# NUC029AN_v1 register map
File version: 1.0
Registers are 32-bit, read-write, reset 0x0 unless marked. A register's access mark holds for its fields unless they carry their own. Offsets are from the block's base; [hi:lo] are bit positions; 'fields as' and 'values as' point back to an identical list.

## UART0 — UART Register Map
Base 0x40050000
0x00 UA_RBR ro reset not defined — UART Receive Buffer Register
  [7:0] RBR — Receive Buffer Register (Read Only). By reading this register, the UART will return an 8-bit data received from RX pin (LSB first).
0x00 UA_THR wo reset not defined (alternate view of UA_RBR) — UART Transmit Holding Register
  [7:0] THR — Transmit Holding Register. By writing to this register, the UART will send out an 8-bit data through the TX pin (LSB first).
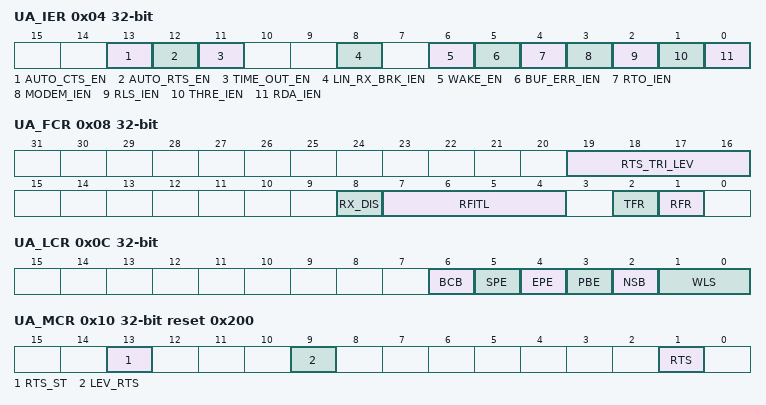
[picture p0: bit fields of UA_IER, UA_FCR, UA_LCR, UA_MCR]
0x04 UA_IER — UART Interrupt Enable Register
  [13] AUTO_CTS_EN — CTS Auto Flow Control Enable. When CTS auto-flow is enabled, the UART will send data to external device when CTS input assert (UART will not send data to device until CTS is asserted).
    0=Disable CTS auto flow control; 1=Enable CTS auto flow control
  [12] AUTO_RTS_EN — RTS Auto Flow Control Enable. When RTS auto-flow is enabled, if the number of bytes in the RX FIFO equals the UA_FCR [RTS_TRI_LEV], the UART will de-assert RTS signal.
    0=Disable RTS auto flow control; 1=Enable RTS auto flow control
  [11] TIME_OUT_EN — Time Out Counter Enable
    0=Disable Time-out counter; 1=Enable Time-out counter
  [8] LIN_RX_BRK_IEN — LIN RX Break Field Detected Interrupt Enable. Note: This field is used for LIN function mode.
    0=Mask off Lin bus RX break filed interrupt; 1=Enable Lin bus RX break filed interrupt
  [6] WAKE_EN — Wake Up CPU Function Enable
    0=Disable UART wake up CPU function; 1=Enable wake up function, when the system is in deep sleep mode, an external CTS change will wake up CPU from deep sleep mode
  [5] BUF_ERR_IEN — Buffer Error Interrupt Enable
    0=Mask off INT_BUF_ERR; 1=Enable INT_BUF_ERR
  [4] RTO_IEN — RX Time Out Interrupt Enable
    0=Mask off INT_TOUT; 1=Enable INT_TOUT
  [3] MODEM_IEN — Modem Status Interrupt Enable
    0=Mask off INT_MODEM; 1=Enable INT_MODEM
  [2] RLS_IEN — Receive Line Status Interrupt Enable
    0=Mask off INT_RLS; 1=Enable INT_RLS
  [1] THRE_IEN — Transmit Holding Register Empty Interrupt Enable
    0=Mask off INT_THRE; 1=Enable INT_THRE
  [0] RDA_IEN — Receive Data Available Interrupt Enable.
    0=Mask off INT_RDA; 1=Enable INT_RDA
0x08 UA_FCR — UART FIFO Control Register
  [19:16] RTS_TRI_LEV — RTS Trigger Level for Auto-flow Control Use
  [8] RX_DIS — Receiver Disable register. The receiver is disabled or not (set 1 is disable receiver). Note: This field is used for RS-485 Normal Multi-drop mode. It should be programmed before UA_ALT_CSR [RS-485_NMM] is programmed.
    0=Enable Receiver; 1=Disable Receiver
  [7:4] RFITL — RX FIFO Interrupt (INT_RDA) Trigger Level
  [2] TFR — TX Field Software Reset. When TX_RST is set, all the byte in the transmit FIFO and TX internal state machine are cleared. Note: This bit will auto clear needs at least 3 UART engine clock cycles.
    0=Writing 0 to this bit has no effect; 1=Writing 1 to this bit will reset the TX internal state machine and pointers
  [1] RFR — RX Field Software Reset. When RX_RST is set, all the byte in the receiver FIFO and RX internal state machine are cleared. Note: This bit will auto clear needs at least 3 UART engine clock cycles.
    0=Writing 0 to this bit has no effect; 1=Writing 1 to this bit will reset the RX internal state machine and pointers
0x0C UA_LCR — UART Line Control Register
  [6] BCB — Break Control Bit. When this bit is set to logic 1, the serial data output (TX) is forced to the Spacing State (logic 0). This bit acts only on TX and has no effect on the transmitter logic.
  [5] SPE — Stick Parity Enable
    0=Disable stick parity; 1=When bits PBE , EPE and SPE are set, the parity bit is transmitted and checked as cleared. When PBE and SPE are set and EPE is cleared, the parity bit is transmitted and checked as set
  [4] EPE — Even Parity Enable. This bit has effect only when bit 3 (parity bit enable) is set.
    0=Odd number of logic 1's are transmitted or checked in the data word and parity bits; 1=Even number of logic 1's are transmitted or checked in the data word and parity bits
  [3] PBE — Parity Bit Enable
    0=Parity bit is not generated (transmit data) or checked (receive data) during transfer; 1=Parity bit is generated or checked between the last data word bit and stop bit of the serial data
  [2] NSB — Number of "STOP bit"
    0=1 STOP bit; 1=2 STOP bits (1.5 STOP bits if WLS[1:0]=00)
  [1:0] WLS — Word Length Select
0x10 UA_MCR reset 0x200 — UART Modem Control Register
  [13] RTS_ST ro — RTS Pin State (Read Only). This bit is the output pin status of RTS.
  [9] LEV_RTS — RTS Trigger Level. This bit can change the RTS trigger level.
    0=low level triggered; 1=high level triggered
  [1] RTS — RTS (Request-To-Send) Signal
    0=Drive RTS pin to logic 1 (If the LEV_RTS set to low level triggered). Drive RTS pin to logic 0 (If the LEV_RTS set to high level triggered); 1=Drive RTS pin to logic 0 (If the LEV_RTS set to low level triggered). Drive RTS pin to logic 1 (If the LEV_RTS set to high level triggered)
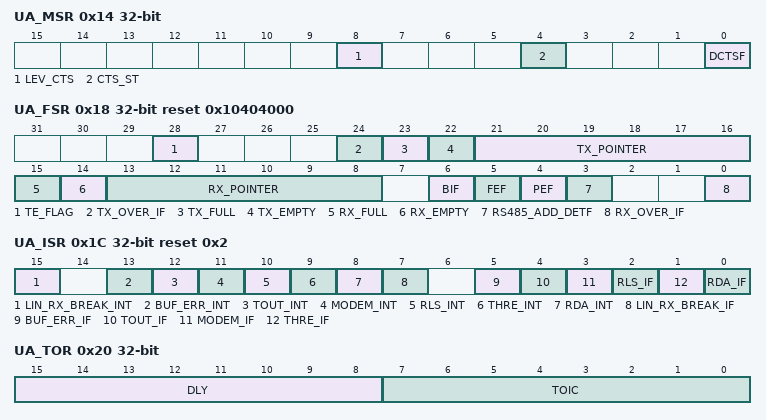
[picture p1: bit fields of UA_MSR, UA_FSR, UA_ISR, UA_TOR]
0x14 UA_MSR — UART Modem Status Register
  [8] LEV_CTS — CTS Trigger Level. This bit can change the CTS trigger level.
    0=low level triggered; 1=high level triggered
  [4] CTS_ST ro — CTS Pin Status (Read Only). This bit is the pin status of CTS when UART clock is enabled, and CTS multi-function port is selected.
  [0] DCTSF ro — Detect CTS State Change Flag (Read Only). This bit is set whenever CTS input has change state, and it will generate Modem interrupt to CPU when UA_IER [MODEM_IEN] is set to 1. Software can write 1 to clear this bit to zero
0x18 UA_FSR reset 0x10404000 — UART FIFO Status Register
  [28] TE_FLAG ro — Transmitter Empty Flag (Read Only). Bit is set by hardware when TX FIFO (UA_THR) is empty and the STOP bit of the last byte has been transmitted. Bit is cleared automatically when TX FIFO is not empty or the last byte transmission has not completed.
  [24] TX_OVER_IF ro — TX Overflow Error Interrupt Flag (Read Only). If TX FIFO (UA_THR) is full, an additional write to UA_THR will cause this bit to logic 1. Note: This bit is read only, but can be cleared by writing '1' to it.
  [23] TX_FULL ro — Transmitter FIFO Full (Read Only). This bit indicates TX FIFO full or not. This bit is set when TX_POINTER is equal to 16, otherwise is cleared by hardware.
  [22] TX_EMPTY ro — Transmitter FIFO Empty (Read Only). This bit indicates TX FIFO empty or not. When the last byte of TX FIFO has been transferred to Transmitter Shift Register, hardware sets this bit high. It will be cleared when writing data into THR (TX FIFO not empty).
  [21:16] TX_POINTER ro — TX FIFO Pointer (Read Only). This field indicates the TX FIFO Buffer Pointer. When CPU writes one byte into UA_THR, TX_POINTER increases one. When one byte of TX FIFO is transferred to Transmitter Shift Register, TX_POINTER decreases one. When TX_POINTER is equal to 16, TX_FULL is set. At this moment, TX_POINTER is cleared immediately by hardware.
  [15] RX_FULL ro — Receiver FIFO Full (Read Only). This bit initiates RX FIFO full or not. This bit is set when RX_POINTER is equal to 16, otherwise is cleared by hardware.
  [14] RX_EMPTY ro — Receiver FIFO Empty (Read Only). This bit initiate RX FIFO empty or not. When the last byte of RX FIFO has been read by CPU, hardware sets this bit high. It will be cleared when UART receives any new data.
  [13:8] RX_POINTER ro — RX FIFO Pointer (Read Only). This field indicates the RX FIFO Buffer Pointer. When UART receives one byte from external device, RX_POINTER increases one. When one byte of RX FIFO is read by CPU, RX_POINTER decreases one. When RX_POINTER is equal to 16, RX_FULL is set. At this moment, RX_POINTER is cleared immediately by hardware.
  [6] BIF ro — Break Interrupt Flag (Read Only). This bit is set to a logic 1 whenever the received data input(RX) is held in the "spacing state" (logic 0) for longer than a full word transmission time (that is, the total time of "start bit" + data bits + parity + stop bits) and is reset whenever the CPU writes 1 to this bit. Note: This bit is read only, but can be cleared by writing '1' to UA_FCR [RFR]
  [5] FEF ro — Framing Error Flag (Read Only). This bit is set to logic 1 whenever the received character does not have a valid "stop bit" (that is, the stop bit following the last data bit or parity bit is detected as a logic 0), and is reset whenever the CPU writes 1 to this bit. Note: This bit is read only, but can be cleared by writing '1' to UA_FCR [RFR]
  [4] PEF ro — Parity Error Flag (Read Only). This bit is set to logic 1 whenever the received character does not have a valid "parity bit", and is reset whenever the CPU writes 1 to this bit. Note: This bit is read only, but can be cleared by writing '1' to UA_FCR[RFR]
  [3] RS485_ADD_DETF ro — RS-485 Address Byte Detection Flag (Read Only). Note: This field is used for RS-485 function mode. Note: This bit is read only, but can be cleared by writing '1' to it.
  [0] RX_OVER_IF ro — RX Overflow Error IF (Read Only). This bit is set when RX FIFO overflow. If the number of bytes of received data is greater than RX_FIFO (UA_RBR) size, 64/16 bytes of UART0/UART1, this bit will be set. Note: This bit is read only, but can be cleared by writing '1' to it.
0x1C UA_ISR reset 0x2 — UART Interrupt Status Register
  [15] LIN_RX_BREAK_INT ro — LIN Bus RX Break Field Detected Interrupt Indicator (Read Only). This bit is set if LIN_RX_BRK_IEN and LIN_RX_BREAK_IF are both set to 1.
    0=No LIN RX Break interrupt is generated; 1=The LIN RX Break interrupt is generated
  [13] BUF_ERR_INT ro — Buffer Error Interrupt Indicator (Read Only). This bit is set if BUF_ERR_IEN and BUF_ERR_IF are both set to 1.
    0=No buffer error interrupt is generated; 1=The buffer error interrupt is generated
  [12] TOUT_INT ro — Time Out Interrupt Indicator (Read Only). This bit is set if TOUT_IEN and TOUT_IF are both set to 1.
    0=No Tout interrupt is generated; 1=The Tout interrupt is generated
  [11] MODEM_INT ro — MODEM Status Interrupt Indicator (Read Only). This bit is set if MODEM_IEN and MODEM_IF are both set to 1.
    0=No Modem interrupt is generated; 1=The Modem interrupt is generated
  [10] RLS_INT ro — Receive Line Status Interrupt Indicator (Read Only). This bit is set if RLS_IEN and RLS_IF are both set to 1.
    0=No RLS interrupt is generated; 1=The RLS interrupt is generated
  [9] THRE_INT ro — Transmit Holding Register Empty Interrupt Indicator (Read Only). This bit is set if THRE_IEN and THRE_IF are both set to 1.
    0=No THRE interrupt is generated; 1=The THRE interrupt is generated
  [8] RDA_INT ro — Receive Data Available Interrupt Indicator (Read Only). This bit is set if RDA_IEN and RDA_IF are both set to 1.
    0=No RDA interrupt is generated; 1=The RDA interrupt is generated
  [7] LIN_RX_BREAK_IF ro — LIN Bus RX Break Field Detected Flag (Read Only). This bit is set when RX received LIN Break Field. If UA_IER [LIN_RX_BRK_IEN] is enabled the LIN RX Break interrupt will be generated. Note: This bit is read only, but can be cleared by writing '1' to it.
  [5] BUF_ERR_IF ro — Buffer Error Interrupt Flag (Read Only). This bit is set when the TX or RX FIFO overflows or Break Interrupt Flag or Parity Error Flag or Frame Error Flag (TX_OVER_IF or RX_OVER_IF ) is set. When BUF_ERR_IF is set, the transfer is not correct. If UA_IER [BUF_ERR_IEN] is enabled, the buffer error interrupt will be generated.
  [4] TOUT_IF ro — Time Out Interrupt Flag (Read Only). This bit is set when the RX FIFO is not empty and no activities occurred in the RX FIFO and the time out counter equal to TOIC. If UA_IER [TOUT_IEN] is enabled, the Tout interrupt will be generated. Note: This bit is read only and user can read UA_RBR (RX is in active) to clear it.
  [3] MODEM_IF ro — MODEM Interrupt Flag (Read Only). Note: This bit is read only and reset to 0 when bit DCTSF is cleared by a write 1 on DCTSF.
  [2] RLS_IF ro — Receive Line Interrupt Flag (Read Only). This bit is set when the RX receive data have parity error, framing error or break error (at least one of 3 bits, BIF, FEF and PEF, is set). If UA_IER [RLS_IEN] is enabled, the RLS interrupt will be generated. Note: This bit is read only and reset to 0 when all bits of BIF, FEF and PEF are cleared.
  [1] THRE_IF ro — Transmit Holding Register Empty Interrupt Flag (Read Only). This bit is set when the last data of TX FIFO is transferred to Transmitter Shift Register. If UA_IER [THRE_IEN] is enabled, the THRE interrupt will be generated. Note: This bit is read only and it will be cleared when writing data into THR (TX FIFO not empty).
  [0] RDA_IF ro — Receive Data Available Interrupt Flag (Read Only). When the number of bytes in the RX FIFO equals the RFITL then the RDA_IF will be set. If UA_IER [RDA_IEN] is enabled, the RDA interrupt will be generated. Note: This bit is read only and it will be cleared when the number of unread bytes of RX FIFO drops below the threshold level (RFITL).
0x20 UA_TOR — UART Time Out Register
  [15:8] DLY — TX Delay time value. This field is use to programming the transfer delay time between the last stop bit and next start bit.
  [7:0] TOIC — Time Out Interrupt Comparator
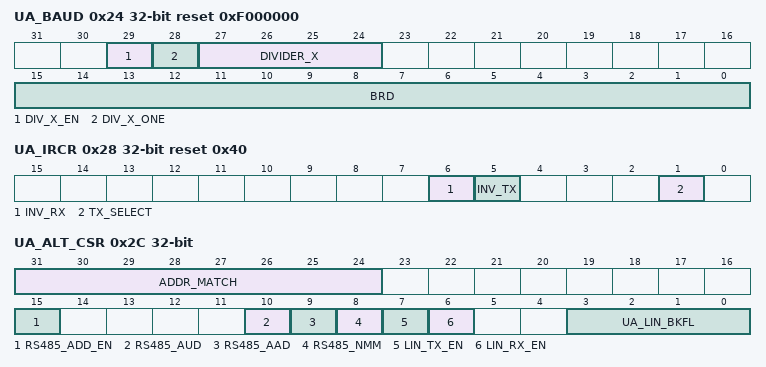
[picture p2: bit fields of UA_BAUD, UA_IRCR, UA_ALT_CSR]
0x24 UA_BAUD reset 0xF000000 — UART Baud Rate Divisor Register
  [29] DIV_X_EN — Divider X Enable. Refer to the table below for more information. Note: When in IrDA mode, this bit must disable.
    0=Disable divider X (the equation of M = 16); 1=Enable divider X (the equation of M = X+1, but DIVIDER_X [27:24] must = 8)
  [28] DIV_X_ONE — Divider X equal 1. Refer to the Table 6.114 below for more information.
    0=Divider M = X (the equation of M = X+1, but DIVIDER_X[27:24] must = 8); 1=Divider M = 1 (the equation of M = 1, but BRD [15:0] must = 3)
  [27:24] DIVIDER_X
  [15:0] BRD — Baud Rate Divider. The field indicated the baud rate divider
0x28 UA_IRCR reset 0x40 — UART IrDA Control Register
  [6] INV_RX
    0=No inversion; 1=Inverse RX input signal
  [5] INV_TX
    0=No inversion; 1=Inverse TX output signal
  [1] TX_SELECT
    0=Enable IrDA receiver; 1=Enable IrDA transmitter
0x2C UA_ALT_CSR — UART Alternate Control/Status Register
  [31:24] ADDR_MATCH — Address match value register. This field contains the RS-485 address match values. Note: This field is used for RS-485 auto address detection mode.
  [15] RS485_ADD_EN — RS-485 Address Detection Enable. This bit is use to enable RS-485 address detection mode. Note: This field is used for RS-485 any operation mode.
    0=Disable address detection mode; 1=Enable address detection mode
  [10] RS485_AUD — RS-485 Auto Direction Mode (AUD). Note: It can be active with RS-485_AAD or RS-485_NMM operation mode.
    0=Disable RS-485 Auto Direction Operation Mode (AUO); 1=Enable RS-485 Auto Direction Operation Mode (AUO)
  [9] RS485_AAD — RS-485 Auto Address Detection Operation Mode (AAD). Note: It can't be active with RS-485_NMM operation mode.
    0=Disable RS-485 Auto Address Detection Operation Mode (AAD); 1=Enable RS-485 Auto Address Detection Operation Mode (AAD)
  [8] RS485_NMM — RS-485 Normal Multi-drop Operation Mode (NMM). Note: It can't be active with RS-485_AAD operation mode.
    0=Disable RS-485 Normal Multi-drop Operation Mode (NMM); 1=Enable RS-485 Normal Multi-drop Operation Mode (NMM)
  [7] LIN_TX_EN — LIN TX Break Mode Enable. Note: When TX break field transfer operation finished, this bit will be cleared automatically.
    0=Disable LIN TX Break Mode; 1=Enable LIN TX Break Mode
  [6] LIN_RX_EN — LIN RX Enable
    0=Disable LIN RX mode; 1=Enable LIN RX mode
  [3:0] UA_LIN_BKFL — UART LIN Break Field Length. This field indicates a 4-bit LIN TX break field count. Note: This break field length is UA_LIN_BKFL + 2
0x30 UA_FUN_SEL — UART Function Select Register
  [1:0] FUN_SEL — Function Select Enable
    0=UART Function; 1=Enable LIN Function; 2=Enable IrDA Function; 3=Enable RS-485 Function

## UART1 — UART Register Map
Base 0x40150000
Registers as UART0; these are added or differ:
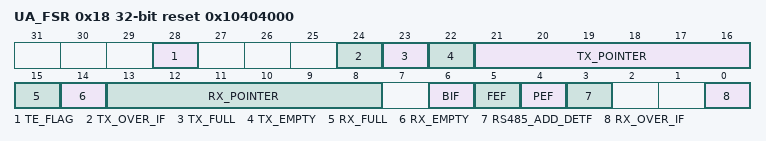
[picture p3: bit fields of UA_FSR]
0x18 UA_FSR reset 0x10404000 — UART FIFO Status Register
  fields as UART0.UA_FSR
